AUTOSAR XML (schema 00044)
package /E40_Platform_System_SystemPackage/Components
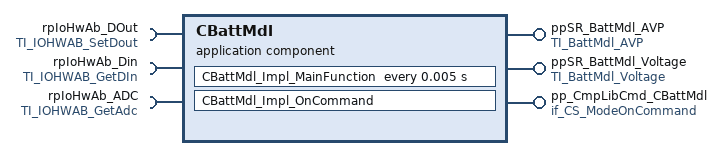
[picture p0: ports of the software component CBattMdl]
  application sw component type CBattMdl
    provide port ppSR_BattMdl_AVP: provided-interface=TI_BattMdl_AVP
      provided-com-specs:
        data-element=HVP0Flag, init-value=constant-reference=CBattMdlHVP0FlagValue0
        data-element=HVSD{0..4}Flag, init-value=constant-reference=CBattMdlHVSD{0..4}FlagValue0
        data-element=LVP0Flag, init-value=constant-reference=CBattMdlLVP0FlagValue0
        data-element=LVP1Flag, init-value=constant-reference=CBattMdlLVP1FlagValue0
        data-element=LVSD{0..4}Flag, init-value=constant-reference=CBattMdlLVSD{0..4}FlagValue0
        data-element=SVPFlag, init-value=constant-reference=CBattMdlSVPFlagValue0
    provide port ppSR_BattMdl_Voltage: nonqueued-sender-com-spec{data-element=OverVoltageInterruptFlag, init-value=constant-reference=CBattMdlOverVoltageInterruptFlagValue0}, provided-interface=TI_BattMdl_Voltage
    provide port pp_CmpLibCmd_CBattMdl: server-com-spec{operation=Impl_OnCommand, queue-length=1}, provided-interface=if_CS_ModeOnCommand
    require port rpIoHwAb_DOut: required-com-specs=[SetOutputGroup, SetOutputPin], required-interface=TI_IOHWAB_SetDout
    require port rpIoHwAb_Din: required-com-specs=[GetAsyncRawInput, GetInputGroup, GetProcessedInput, GetSyncRawInput], required-interface=TI_IOHWAB_GetDIn
    require port rpIoHwAb_ADC: required-com-specs=[GetAsyncRawAdc, GetProcessedAdc, GetSyncRawAdc], required-interface=TI_IOHWAB_GetAdc
    behavior IB_CBattMdl
      timing event TECBattMdl_Impl_MainFunction: start-on-event=CBattMdl_Impl_MainFunction, period=0.005
      operation invoked event OIE_pp_CmpLibCmd_CBattMdl_CBattMdl_Impl_OnCommandTrigByImpl_OnCommand: start-on-event=CBattMdl_Impl_OnCommand, operation=pp_CmpLibCmd_CBattMdl.Impl_OnCommand
      port-api-options:
        enable-take-address=false, indirect-api=false, port=ppSR_BattMdl_AVP
        enable-take-address=false, indirect-api=false, port=ppSR_BattMdl_Voltage
        enable-take-address=false, indirect-api=false, port=pp_CmpLibCmd_CBattMdl
        enable-take-address=false, indirect-api=false, port=rpIoHwAb_DOut
        enable-take-address=false, indirect-api=false, port=rpIoHwAb_Din
        enable-take-address=false, indirect-api=false, port=rpIoHwAb_ADC
      runnable CBattMdl_Impl_MainFunction: can-be-invoked-concurrently=true
        data-send-points:
          15 x access:
            DWA_ppSR_BattMdl_AVP_HVP0Flag: accessed-variable=ppSR_BattMdl_AVP.HVP0Flag
            DWA_ppSR_BattMdl_AVP_HVSD{0..4}Flag: accessed-variable=ppSR_BattMdl_AVP.HVSD{0..4}Flag
            DWA_ppSR_BattMdl_AVP_LVP0Flag: accessed-variable=ppSR_BattMdl_AVP.LVP0Flag
            DWA_ppSR_BattMdl_AVP_LVP1Flag: accessed-variable=ppSR_BattMdl_AVP.LVP1Flag
            DWA_ppSR_BattMdl_AVP_LVSD{0..4}Flag: accessed-variable=ppSR_BattMdl_AVP.LVSD{0..4}Flag
            DWA_ppSR_BattMdl_AVP_SVPFlag: accessed-variable=ppSR_BattMdl_AVP.SVPFlag
            DWA_ppSR_BattMdl_Voltage_OverVoltageInterruptFlag: accessed-variable=ppSR_BattMdl_Voltage.OverVoltageInterruptFlag
        9 x sync call:
          OA_rpIoHwAb_DOut_SetOutputGroup: operation=rpIoHwAb_DOut.SetOutputGroup
          OA_rpIoHwAb_DOut_SetOutputPin: operation=rpIoHwAb_DOut.SetOutputPin
          OA_rpIoHwAb_Din_GetAsyncRawInput: operation=rpIoHwAb_Din.GetAsyncRawInput
          OA_rpIoHwAb_Din_GetProcessedInput: operation=rpIoHwAb_Din.GetProcessedInput
          OA_rpIoHwAb_Din_GetSyncRawInput: operation=rpIoHwAb_Din.GetSyncRawInput
          OA_rpIoHwAb_Din_GetInputGroup: operation=rpIoHwAb_Din.GetInputGroup
          OA_rpIoHwAb_ADC_GetAsyncRawAdc: operation=rpIoHwAb_ADC.GetAsyncRawAdc
          OA_rpIoHwAb_ADC_GetSyncRawAdc: operation=rpIoHwAb_ADC.GetSyncRawAdc
          OA_rpIoHwAb_ADC_GetProcessedAdc: operation=rpIoHwAb_ADC.GetProcessedAdc
      runnable CBattMdl_Impl_OnCommand: can-be-invoked-concurrently=true
        data-send-points:
          15 x access:
            DWA_ppSR_BattMdl_AVP_HVP0Flag: accessed-variable=ppSR_BattMdl_AVP.HVP0Flag
            DWA_ppSR_BattMdl_AVP_HVSD{0..4}Flag: accessed-variable=ppSR_BattMdl_AVP.HVSD{0..4}Flag
            DWA_ppSR_BattMdl_AVP_LVP0Flag: accessed-variable=ppSR_BattMdl_AVP.LVP0Flag
            DWA_ppSR_BattMdl_AVP_LVP1Flag: accessed-variable=ppSR_BattMdl_AVP.LVP1Flag
            DWA_ppSR_BattMdl_AVP_LVSD{0..4}Flag: accessed-variable=ppSR_BattMdl_AVP.LVSD{0..4}Flag
            DWA_ppSR_BattMdl_AVP_SVPFlag: accessed-variable=ppSR_BattMdl_AVP.SVPFlag
            DWA_ppSR_BattMdl_Voltage_OverVoltageInterruptFlag: accessed-variable=ppSR_BattMdl_Voltage.OverVoltageInterruptFlag
        9 x sync call:
          OA_rpIoHwAb_DOut_SetOutputGroup: operation=rpIoHwAb_DOut.SetOutputGroup
          OA_rpIoHwAb_DOut_SetOutputPin: operation=rpIoHwAb_DOut.SetOutputPin
          OA_rpIoHwAb_Din_GetAsyncRawInput: operation=rpIoHwAb_Din.GetAsyncRawInput
          OA_rpIoHwAb_Din_GetProcessedInput: operation=rpIoHwAb_Din.GetProcessedInput
          OA_rpIoHwAb_Din_GetSyncRawInput: operation=rpIoHwAb_Din.GetSyncRawInput
          OA_rpIoHwAb_Din_GetInputGroup: operation=rpIoHwAb_Din.GetInputGroup
          OA_rpIoHwAb_ADC_GetAsyncRawAdc: operation=rpIoHwAb_ADC.GetAsyncRawAdc
          OA_rpIoHwAb_ADC_GetSyncRawAdc: operation=rpIoHwAb_ADC.GetSyncRawAdc
          OA_rpIoHwAb_ADC_GetProcessedAdc: operation=rpIoHwAb_ADC.GetProcessedAdc
  swc implementation IMPL_CBattMdl: behavior=IB_CBattMdl
